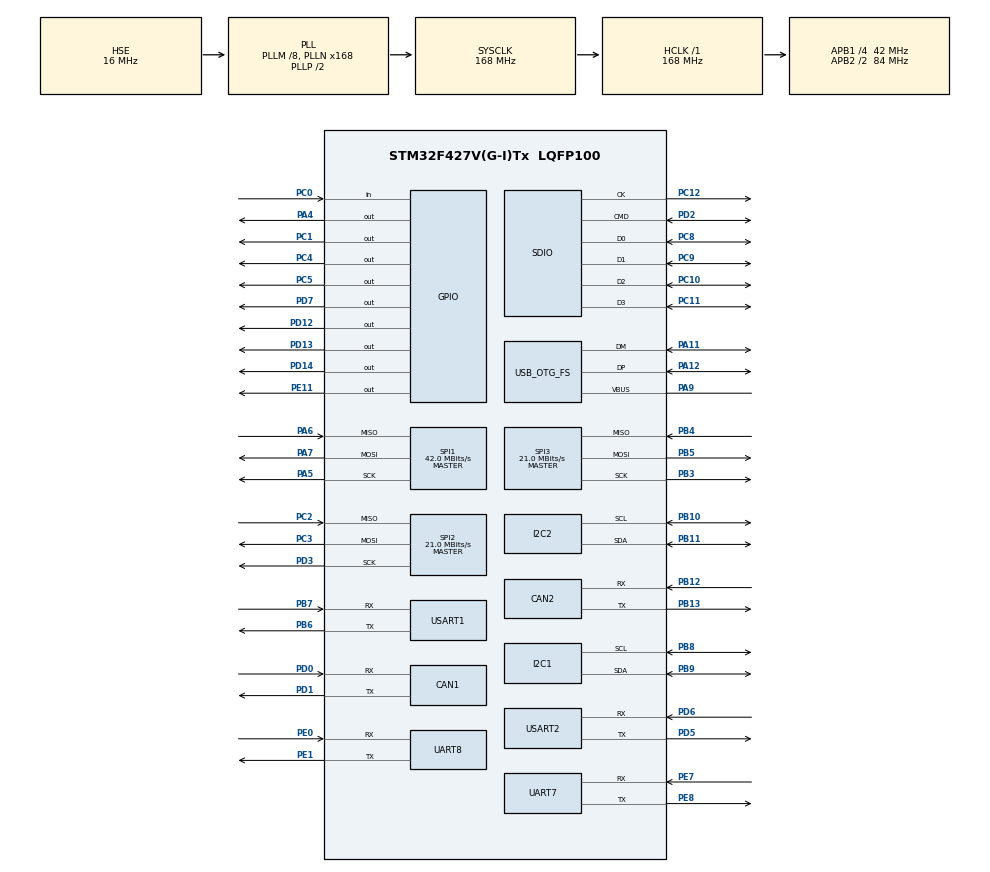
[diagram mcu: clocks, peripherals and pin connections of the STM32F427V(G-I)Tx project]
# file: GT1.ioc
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CAN1.BS1=CAN_BS1_1TQ
CAN1.BS2=CAN_BS2_1TQ
CAN1.CalculateTimeBit=1142
CAN1.CalculateTimeQuantum=380.95238095238096
CAN2.BS1=CAN_BS1_1TQ
CAN2.BS2=CAN_BS2_1TQ
CAN2.CalculateTimeBit=1142
CAN2.CalculateTimeQuantum=380.95238095238096
Mcu.Family=STM32F4
Mcu.Name=STM32F427V(G-I)Tx
Mcu.Package=LQFP100
NVIC.OTG_FS_IRQn=true\:0\:0\:false\:false\:true
NVIC.PriorityGroup=NVIC_PRIORITYGROUP_4
NVIC.TIM3_IRQn=true\:0\:0\:false\:false\:true
NVIC.TIM4_IRQn=true\:0\:0\:false\:false\:true
PA0/WKUP.Signal=UART4_TX
PA1.Signal=UART4_RX
PA11.Mode=Device_Only
PA11.Signal=USB_OTG_FS_DM
PA12.Mode=Device_Only
PA12.Signal=USB_OTG_FS_DP
PA13.Mode=Serial_Wire
PA13.Signal=SYS_JTMS-SWDIO
PA14.Mode=Serial_Wire
PA14.Signal=SYS_JTCK-SWCLK
PA4.Signal=GPIO_Output
PA5.Mode=Full_Duplex_Master
PA5.Signal=SPI1_SCK
PA6.Mode=Full_Duplex_Master
PA6.Signal=SPI1_MISO
PA7.Mode=Full_Duplex_Master
PA7.Signal=SPI1_MOSI
PA9.Mode=Activate_VBUS
PA9.Signal=USB_OTG_FS_VBUS
PB1.Signal=TIM1_CH3N
PB10.Mode=I2C
PB10.Signal=I2C2_SCL
PB11.Mode=I2C
PB11.Signal=I2C2_SDA
PB12.Mode=Slave
PB12.Signal=CAN2_RX
PB13.Mode=Slave
PB13.Signal=CAN2_TX
PB3.Mode=Full_Duplex_Master
PB3.Signal=SPI3_SCK
PB4.Mode=Full_Duplex_Master
PB4.Signal=SPI3_MISO
PB5.Mode=Full_Duplex_Master
PB5.Signal=SPI3_MOSI
PB6.Mode=Asynchronous
PB6.Signal=USART1_TX
PB7.Mode=Asynchronous
PB7.Signal=USART1_RX
PB8.Mode=I2C
PB8.Signal=I2C1_SCL
PB9.Mode=I2C
PB9.Signal=I2C1_SDA
PC0.Signal=GPIO_Input
PC1.Signal=GPIO_Output
PC10.Mode=SD_4_bits_Wide_bus
PC10.Signal=SDIO_D2
PC11.Mode=SD_4_bits_Wide_bus
PC11.Signal=SDIO_D3
PC12.Mode=SD_4_bits_Wide_bus
PC12.Signal=SDIO_CK
PC14/OSC32_IN.Mode=LSE-External-Oscillator
PC14/OSC32_IN.Signal=RCC_OSC32_IN
PC15/OSC32_OUT.Mode=LSE-External-Oscillator
PC15/OSC32_OUT.Signal=RCC_OSC32_OUT
PC2.Mode=Full_Duplex_Master
PC2.Signal=SPI2_MISO
PC3.Mode=Full_Duplex_Master
PC3.Signal=SPI2_MOSI
PC4.Signal=GPIO_Output
PC5.Signal=GPIO_Output
PC6.Signal=USART6_TX
PC7.Signal=USART6_RX
PC8.Mode=SD_4_bits_Wide_bus
PC8.Signal=SDIO_D0
PC9.Mode=SD_4_bits_Wide_bus
PC9.Signal=SDIO_D1
PD0.Mode=Master
PD0.Signal=CAN1_RX
PD1.Mode=Master
PD1.Signal=CAN1_TX
PD12.Signal=GPIO_Output
PD13.Signal=GPIO_Output
PD14.Signal=GPIO_Output
PD2.Mode=SD_4_bits_Wide_bus
PD2.Signal=SDIO_CMD
PD3.Mode=Full_Duplex_Master
PD3.Signal=SPI2_SCK
PD5.Mode=Asynchronous
PD5.Signal=USART2_TX
PD6.Mode=Asynchronous
PD6.Signal=USART2_RX
PD7.Signal=GPIO_Output
PD8.Signal=USART3_TX
PD9.Signal=USART3_RX
PE0.Mode=Asynchronous
PE0.Signal=UART8_RX
PE1.Mode=Asynchronous
PE1.Signal=UART8_TX
PE11.Signal=GPIO_Output
PE7.Mode=Asynchronous
PE7.Signal=UART7_RX
PE8.Mode=Asynchronous
PE8.Signal=UART7_TX
PH0/OSC_IN.Mode=HSE-External-Oscillator
PH0/OSC_IN.Signal=RCC_OSC_IN
PH1/OSC_OUT.Mode=HSE-External-Oscillator
PH1/OSC_OUT.Signal=RCC_OSC_OUT
ProjectManager.HeapSize=0x200
ProjectManager.StackSize=0x400
ProjectManager.TargetToolchain=MDK-ARM V5
RCC.48MHZClocksFreq_Value=48000000
RCC.AHBFreq_Value=168000000
RCC.APB1CLKDivider=RCC_HCLK_DIV4
RCC.APB1Freq_Value=42000000
RCC.APB1TimFreq_Value=84000000
RCC.APB2CLKDivider=RCC_HCLK_DIV2
RCC.APB2Freq_Value=84000000
RCC.APB2TimFreq_Value=168000000
RCC.CortexFreq_Value=168000000
RCC.HCLKFreq_Value=168000000
RCC.HSE_VALUE=16000000
RCC.HSI_VALUE=16000000
RCC.PLLM=8
RCC.PLLN=168
RCC.PLLQ=7
RCC.RCC_RTC_Clock_Source=RCC_RTCCLKSOURCE_LSI
RCC.RCC_RTC_Clock_SourceVirtual=RCC_RTCCLKSOURCE_LSE
RCC.SYSCLKFreq_VALUE=168000000
RCC.SYSCLKSource=RCC_SYSCLKSOURCE_PLLCLK
RCC.VCOOutputFreq_Value=336000000
SDIO.BusWide=SDIO_BUS_WIDE_1B
SDIO.WideMode=SDIO_BUS_WIDE_4B
SPI1.BaudRatePrescaler=SPI_BAUDRATEPRESCALER_2
SPI1.CalculateBaudRate=42.0 MBits/s
SPI1.Mode=SPI_MODE_MASTER
SPI2.BaudRatePrescaler=SPI_BAUDRATEPRESCALER_2
SPI2.CalculateBaudRate=21.0 MBits/s
SPI2.Mode=SPI_MODE_MASTER
SPI3.BaudRatePrescaler=SPI_BAUDRATEPRESCALER_2
SPI3.CalculateBaudRate=21.0 MBits/s
SPI3.Mode=SPI_MODE_MASTER
TIM3.Period=1000
TIM3.Prescaler=48000
TIM4.Period=2000
TIM4.Prescaler=42000
USB_DEVICE.CLASS_NAME-CDC_FS=CDC
USB_DEVICE.CLASS_NAME_FS=CDC
USB_DEVICE.USBD_HandleTypeDef-CDC_FS=hUsbDeviceFS
USB_DEVICE.VirtualMode-CDC_FS=Cdc
USB_DEVICE.VirtualModeFS=Cdc_FS
USB_OTG_FS.VirtualMode=Device_Only
VP_FATFS_VS_SDIO.Mode=SDIO
VP_RTC_VS_RTC_Activate.Mode=RTC_Enabled
VP_TIM3_VS_ClockSourceINT.Mode=Internal
VP_TIM4_VS_ClockSourceINT.Mode=Internal
VP_USB_DEVICE_VS_USB_DEVICE_CDC_FS.Mode=CDC_FS
board=GT1

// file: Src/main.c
/**
  ******************************************************************************
  * File Name          : main.c
  * Description        : Main program body
  ******************************************************************************
  *
  * Copyright (c) 2017 STMicroelectronics International N.V.
  * All rights reserved.
  *
  * Redistribution and use in source and binary forms, with or without
  * modification, are permitted, provided that the following conditions are met:
  *
  * 1. Redistribution of source code must retain the above copyright notice,
  *    this list of conditions and the following disclaimer.
  * 2. Redistributions in binary form must reproduce the above copyright notice,
  *    this list of conditions and the following disclaimer in the documentation
  *    and/or other materials provided with the distribution.
  * 3. Neither the name of STMicroelectronics nor the names of other
  *    contributors to this software may be used to endorse or promote products
  *    derived from this software without specific written permission.
  * 4. This software, including modifications and/or derivative works of this
  *    software, must execute solely and exclusively on microcontroller or
  *    microprocessor devices manufactured by or for STMicroelectronics.
  * 5. Redistribution and use of this software other than as permitted under
  *    this license is void and will automatically terminate your rights under
  *    this license.
  *
  * THIS SOFTWARE IS PROVIDED BY STMICROELECTRONICS AND CONTRIBUTORS "AS IS"
  * AND ANY EXPRESS, IMPLIED OR STATUTORY WARRANTIES, INCLUDING, BUT NOT
  * LIMITED TO, THE IMPLIED WARRANTIES OF MERCHANTABILITY, FITNESS FOR A
  * PARTICULAR PURPOSE AND NON-INFRINGEMENT OF THIRD PARTY INTELLECTUAL PROPERTY
  * RIGHTS ARE DISCLAIMED TO THE FULLEST EXTENT PERMITTED BY LAW. IN NO EVENT
  * SHALL STMICROELECTRONICS OR CONTRIBUTORS BE LIABLE FOR ANY DIRECT, INDIRECT,
  * INCIDENTAL, SPECIAL, EXEMPLARY, OR CONSEQUENTIAL DAMAGES (INCLUDING, BUT NOT
  * LIMITED TO, PROCUREMENT OF SUBSTITUTE GOODS OR SERVICES; LOSS OF USE, DATA,
  * OR PROFITS; OR BUSINESS INTERRUPTION) HOWEVER CAUSED AND ON ANY THEORY OF
  * LIABILITY, WHETHER IN CONTRACT, STRICT LIABILITY, OR TORT (INCLUDING
  * NEGLIGENCE OR OTHERWISE) ARISING IN ANY WAY OUT OF THE USE OF THIS SOFTWARE,
  * EVEN IF ADVISED OF THE POSSIBILITY OF SUCH DAMAGE.
  *
  ******************************************************************************
  */
#include "main.h"
#include "stm32f4xx_hal.h"
#include "fatfs.h"
#include "usb_device.h"
#include "usbd_cdc_if.h"

CAN_HandleTypeDef hcan1;
CAN_HandleTypeDef hcan2;

I2C_HandleTypeDef hi2c1;
I2C_HandleTypeDef hi2c2;

RTC_HandleTypeDef hrtc;

SD_HandleTypeDef hsd;
HAL_SD_CardInfoTypedef SDCardInfo;

SPI_HandleTypeDef hspi1;
SPI_HandleTypeDef hspi2;
SPI_HandleTypeDef hspi3;

TIM_HandleTypeDef htim3;
TIM_HandleTypeDef htim4;

UART_HandleTypeDef huart7;
UART_HandleTypeDef huart8;
UART_HandleTypeDef huart1;
UART_HandleTypeDef huart2;

int rearLight_sign = 0;
int power_sign = 0;
int paster_test_sign = 0;
/* USER CODE BEGIN PV */
/* Private variables ---------------------------------------------------------*/

/* USER CODE END PV */

void SystemClock_Config(void);
void Error_Handler(void);
static void MX_GPIO_Init(void);
static void MX_CAN1_Init(void);
static void MX_CAN2_Init(void);
static void MX_I2C1_Init(void);
static void MX_I2C2_Init(void);
static void MX_RTC_Init(void);
static void MX_SDIO_SD_Init(void);
static void MX_SPI1_Init(void);
static void MX_SPI2_Init(void);
static void MX_SPI3_Init(void);
static void MX_UART7_Init(void);
static void MX_UART8_Init(void);
static void MX_USART1_UART_Init(void);
static void MX_USART2_UART_Init(void);
static void MX_TIM4_Init(void);
static void MX_TIM3_Init(void);

/* USER CODE BEGIN PFP */
/* Private function prototypes -----------------------------------------------*/

/* USER CODE END PFP */

int main(void)
{

  /* USER CODE BEGIN 1 */
  int mdelay=0;
	int reset_num=0;
  /* USER CODE END 1 */

  /* MCU Configuration----------------------------------------------------------*/

  /* Reset of all peripherals, Initializes the Flash interface and the Systick. */
  HAL_Init();

  /* Configure the system clock */
  SystemClock_Config();

  /* Initialize all configured peripherals */
  MX_GPIO_Init();
  MX_CAN1_Init();
  MX_CAN2_Init();
  MX_I2C1_Init();
  MX_I2C2_Init();
  MX_RTC_Init();
  MX_SDIO_SD_Init();
  MX_SPI1_Init();
  MX_SPI2_Init();
  MX_SPI3_Init();
  MX_UART7_Init();
  MX_UART8_Init();
  MX_USART1_UART_Init();
  MX_USART2_UART_Init();
  MX_FATFS_Init();
  MX_TIM4_Init();
  MX_TIM3_Init();
  MX_USB_DEVICE_Init();

  /* USER CODE BEGIN 2 */
  //poweron the system
  HAL_GPIO_WritePin(GPIOE,GPIO_PIN_11,0);

  HAL_TIM_Base_Start_IT(&htim3);
	HAL_TIM_Base_Start_IT(&htim4);
  /* USER CODE END 2 */

  /* Infinite loop */
  while (1)
  {
	if(power_sign >= 3)
		HAL_GPIO_WritePin(GPIOE,GPIO_PIN_11,1);
  /* USER CODE BEGIN 3 */
	//CDC_Transmit_FS("GT1 paster test\n\r", 18);
  }
  /* USER CODE END 3 */

}

/** System Clock Configuration
*/
void SystemClock_Config(void)
{

  RCC_OscInitTypeDef RCC_OscInitStruct;
  RCC_ClkInitTypeDef RCC_ClkInitStruct;
  RCC_PeriphCLKInitTypeDef PeriphClkInitStruct;

    /**Configure the main internal regulator output voltage
    */
  __HAL_RCC_PWR_CLK_ENABLE();

  __HAL_PWR_VOLTAGESCALING_CONFIG(PWR_REGULATOR_VOLTAGE_SCALE1);

    /**Initializes the CPU, AHB and APB busses clocks
    */
  RCC_OscInitStruct.OscillatorType = RCC_OSCILLATORTYPE_LSI|RCC_OSCILLATORTYPE_HSE;
  RCC_OscInitStruct.HSEState = RCC_HSE_ON;
  RCC_OscInitStruct.LSIState = RCC_LSI_ON;
  RCC_OscInitStruct.PLL.PLLState = RCC_PLL_ON;
  RCC_OscInitStruct.PLL.PLLSource = RCC_PLLSOURCE_HSE;
  RCC_OscInitStruct.PLL.PLLM = 8;
  RCC_OscInitStruct.PLL.PLLN = 168;
  RCC_OscInitStruct.PLL.PLLP = RCC_PLLP_DIV2;
  RCC_OscInitStruct.PLL.PLLQ = 7;
  if (HAL_RCC_OscConfig(&RCC_OscInitStruct) != HAL_OK)
  {
    Error_Handler();
  }

    /**Initializes the CPU, AHB and APB busses clocks
    */
  RCC_ClkInitStruct.ClockType = RCC_CLOCKTYPE_HCLK|RCC_CLOCKTYPE_SYSCLK
                              |RCC_CLOCKTYPE_PCLK1|RCC_CLOCKTYPE_PCLK2;
  RCC_ClkInitStruct.SYSCLKSource = RCC_SYSCLKSOURCE_PLLCLK;
  RCC_ClkInitStruct.AHBCLKDivider = RCC_SYSCLK_DIV1;
  RCC_ClkInitStruct.APB1CLKDivider = RCC_HCLK_DIV4;
  RCC_ClkInitStruct.APB2CLKDivider = RCC_HCLK_DIV2;

  if (HAL_RCC_ClockConfig(&RCC_ClkInitStruct, FLASH_LATENCY_5) != HAL_OK)
  {
    Error_Handler();
  }

  PeriphClkInitStruct.PeriphClockSelection = RCC_PERIPHCLK_RTC;
  PeriphClkInitStruct.RTCClockSelection = RCC_RTCCLKSOURCE_LSI;
  if (HAL_RCCEx_PeriphCLKConfig(&PeriphClkInitStruct) != HAL_OK)
  {
    Error_Handler();
  }

    /**Configure the Systick interrupt time
    */
  HAL_SYSTICK_Config(HAL_RCC_GetHCLKFreq()/1000);

    /**Configure the Systick
    */
  HAL_SYSTICK_CLKSourceConfig(SYSTICK_CLKSOURCE_HCLK);

  /* SysTick_IRQn interrupt configuration */
  HAL_NVIC_SetPriority(SysTick_IRQn, 0, 0);
}

/* CAN1 init function */
static void MX_CAN1_Init(void)
{

  hcan1.Instance = CAN1;
  hcan1.Init.Prescaler = 16;
  hcan1.Init.Mode = CAN_MODE_NORMAL;
  hcan1.Init.SJW = CAN_SJW_1TQ;
  hcan1.Init.BS1 = CAN_BS1_1TQ;
  hcan1.Init.BS2 = CAN_BS2_1TQ;
  hcan1.Init.TTCM = DISABLE;
  hcan1.Init.ABOM = DISABLE;
  hcan1.Init.AWUM = DISABLE;
  hcan1.Init.NART = DISABLE;
  hcan1.Init.RFLM = DISABLE;
  hcan1.Init.TXFP = DISABLE;
  if (HAL_CAN_Init(&hcan1) != HAL_OK)
  {
    Error_Handler();
  }

}

/* CAN2 init function */
static void MX_CAN2_Init(void)
{

  hcan2.Instance = CAN2;
  hcan2.Init.Prescaler = 16;
  hcan2.Init.Mode = CAN_MODE_NORMAL;
  hcan2.Init.SJW = CAN_SJW_1TQ;
  hcan2.Init.BS1 = CAN_BS1_1TQ;
  hcan2.Init.BS2 = CAN_BS2_1TQ;
  hcan2.Init.TTCM = DISABLE;
  hcan2.Init.ABOM = DISABLE;
  hcan2.Init.AWUM = DISABLE;
  hcan2.Init.NART = DISABLE;
  hcan2.Init.RFLM = DISABLE;
  hcan2.Init.TXFP = DISABLE;
  if (HAL_CAN_Init(&hcan2) != HAL_OK)
  {
    Error_Handler();
  }

}

/* I2C1 init function */
static void MX_I2C1_Init(void)
{

  hi2c1.Instance = I2C1;
  hi2c1.Init.ClockSpeed = 100000;
  hi2c1.Init.DutyCycle = I2C_DUTYCYCLE_2;
  hi2c1.Init.OwnAddress1 = 0;
  hi2c1.Init.AddressingMode = I2C_ADDRESSINGMODE_7BIT;
  hi2c1.Init.DualAddressMode = I2C_DUALADDRESS_DISABLE;
  hi2c1.Init.OwnAddress2 = 0;
  hi2c1.Init.GeneralCallMode = I2C_GENERALCALL_DISABLE;
  hi2c1.Init.NoStretchMode = I2C_NOSTRETCH_DISABLE;
  if (HAL_I2C_Init(&hi2c1) != HAL_OK)
  {
    Error_Handler();
  }

}

/* I2C2 init function */
static void MX_I2C2_Init(void)
{

  hi2c2.Instance = I2C2;
  hi2c2.Init.ClockSpeed = 100000;
  hi2c2.Init.DutyCycle = I2C_DUTYCYCLE_2;
  hi2c2.Init.OwnAddress1 = 0;
  hi2c2.Init.AddressingMode = I2C_ADDRESSINGMODE_7BIT;
  hi2c2.Init.DualAddressMode = I2C_DUALADDRESS_DISABLE;
  hi2c2.Init.OwnAddress2 = 0;
  hi2c2.Init.GeneralCallMode = I2C_GENERALCALL_DISABLE;
  hi2c2.Init.NoStretchMode = I2C_NOSTRETCH_DISABLE;
  if (HAL_I2C_Init(&hi2c2) != HAL_OK)
  {
    Error_Handler();
  }

}

/* RTC init function */
static void MX_RTC_Init(void)
{

    /**Initialize RTC Only
    */
  hrtc.Instance = RTC;
  hrtc.Init.HourFormat = RTC_HOURFORMAT_24;
  hrtc.Init.AsynchPrediv = 127;
  hrtc.Init.SynchPrediv = 255;
  hrtc.Init.OutPut = RTC_OUTPUT_DISABLE;
  hrtc.Init.OutPutPolarity = RTC_OUTPUT_POLARITY_HIGH;
  hrtc.Init.OutPutType = RTC_OUTPUT_TYPE_OPENDRAIN;
  if (HAL_RTC_Init(&hrtc) != HAL_OK)
  {
    Error_Handler();
  }

}

/* SDIO init function */
static void MX_SDIO_SD_Init(void)
{

  hsd.Instance = SDIO;
  hsd.Init.ClockEdge = SDIO_CLOCK_EDGE_RISING;
  hsd.Init.ClockBypass = SDIO_CLOCK_BYPASS_DISABLE;
  hsd.Init.ClockPowerSave = SDIO_CLOCK_POWER_SAVE_DISABLE;
  hsd.Init.BusWide = SDIO_BUS_WIDE_1B;
  hsd.Init.HardwareFlowControl = SDIO_HARDWARE_FLOW_CONTROL_DISABLE;
  hsd.Init.ClockDiv = 0;

}

/* SPI1 init function */
static void MX_SPI1_Init(void)
{

  hspi1.Instance = SPI1;
  hspi1.Init.Mode = SPI_MODE_MASTER;
  hspi1.Init.Direction = SPI_DIRECTION_2LINES;
  hspi1.Init.DataSize = SPI_DATASIZE_8BIT;
  hspi1.Init.CLKPolarity = SPI_POLARITY_LOW;
  hspi1.Init.CLKPhase = SPI_PHASE_1EDGE;
  hspi1.Init.NSS = SPI_NSS_SOFT;
  hspi1.Init.BaudRatePrescaler = SPI_BAUDRATEPRESCALER_2;
  hspi1.Init.FirstBit = SPI_FIRSTBIT_MSB;
  hspi1.Init.TIMode = SPI_TIMODE_DISABLE;
  hspi1.Init.CRCCalculation = SPI_CRCCALCULATION_DISABLE;
  hspi1.Init.CRCPolynomial = 10;
  if (HAL_SPI_Init(&hspi1) != HAL_OK)
  {
    Error_Handler();
  }

}

/* SPI2 init function */
static void MX_SPI2_Init(void)
{

  hspi2.Instance = SPI2;
  hspi2.Init.Mode = SPI_MODE_MASTER;
  hspi2.Init.Direction = SPI_DIRECTION_2LINES;
  hspi2.Init.DataSize = SPI_DATASIZE_8BIT;
  hspi2.Init.CLKPolarity = SPI_POLARITY_LOW;
  hspi2.Init.CLKPhase = SPI_PHASE_1EDGE;
  hspi2.Init.NSS = SPI_NSS_SOFT;
  hspi2.Init.BaudRatePrescaler = SPI_BAUDRATEPRESCALER_2;
  hspi2.Init.FirstBit = SPI_FIRSTBIT_MSB;
  hspi2.Init.TIMode = SPI_TIMODE_DISABLE;
  hspi2.Init.CRCCalculation = SPI_CRCCALCULATION_DISABLE;
  hspi2.Init.CRCPolynomial = 10;
  if (HAL_SPI_Init(&hspi2) != HAL_OK)
  {
    Error_Handler();
  }

}

/* SPI3 init function */
static void MX_SPI3_Init(void)
{

  hspi3.Instance = SPI3;
  hspi3.Init.Mode = SPI_MODE_MASTER;
  hspi3.Init.Direction = SPI_DIRECTION_2LINES;
  hspi3.Init.DataSize = SPI_DATASIZE_8BIT;
  hspi3.Init.CLKPolarity = SPI_POLARITY_LOW;
  hspi3.Init.CLKPhase = SPI_PHASE_1EDGE;
  hspi3.Init.NSS = SPI_NSS_SOFT;
  hspi3.Init.BaudRatePrescaler = SPI_BAUDRATEPRESCALER_2;
  hspi3.Init.FirstBit = SPI_FIRSTBIT_MSB;
  hspi3.Init.TIMode = SPI_TIMODE_DISABLE;
  hspi3.Init.CRCCalculation = SPI_CRCCALCULATION_DISABLE;
  hspi3.Init.CRCPolynomial = 10;
  if (HAL_SPI_Init(&hspi3) != HAL_OK)
  {
    Error_Handler();
  }

}

/* TIM3 init function */
static void MX_TIM3_Init(void)
{

  TIM_ClockConfigTypeDef sClockSourceConfig;
  TIM_MasterConfigTypeDef sMasterConfig;

  htim3.Instance = TIM3;
  htim3.Init.Prescaler = 48000;
  htim3.Init.CounterMode = TIM_COUNTERMODE_UP;
  htim3.Init.Period = 1000;
  htim3.Init.ClockDivision = TIM_CLOCKDIVISION_DIV1;
  if (HAL_TIM_Base_Init(&htim3) != HAL_OK)
  {
    Error_Handler();
  }

  sClockSourceConfig.ClockSource = TIM_CLOCKSOURCE_INTERNAL;
  if (HAL_TIM_ConfigClockSource(&htim3, &sClockSourceConfig) != HAL_OK)
  {
    Error_Handler();
  }

  sMasterConfig.MasterOutputTrigger = TIM_TRGO_RESET;
  sMasterConfig.MasterSlaveMode = TIM_MASTERSLAVEMODE_DISABLE;
  if (HAL_TIMEx_MasterConfigSynchronization(&htim3, &sMasterConfig) != HAL_OK)
  {
    Error_Handler();
  }

}

/* TIM4 init function */
static void MX_TIM4_Init(void)
{

  TIM_ClockConfigTypeDef sClockSourceConfig;
  TIM_MasterConfigTypeDef sMasterConfig;

  htim4.Instance = TIM4;
  htim4.Init.Prescaler = 42000;
  htim4.Init.CounterMode = TIM_COUNTERMODE_UP;
  htim4.Init.Period = 2000;
  htim4.Init.ClockDivision = TIM_CLOCKDIVISION_DIV1;
  if (HAL_TIM_Base_Init(&htim4) != HAL_OK)
  {
    Error_Handler();
  }

  sClockSourceConfig.ClockSource = TIM_CLOCKSOURCE_INTERNAL;
  if (HAL_TIM_ConfigClockSource(&htim4, &sClockSourceConfig) != HAL_OK)
  {
    Error_Handler();
  }

  sMasterConfig.MasterOutputTrigger = TIM_TRGO_RESET;
  sMasterConfig.MasterSlaveMode = TIM_MASTERSLAVEMODE_DISABLE;
  if (HAL_TIMEx_MasterConfigSynchronization(&htim4, &sMasterConfig) != HAL_OK)
  {
    Error_Handler();
  }

}

/* UART7 init function */
static void MX_UART7_Init(void)
{

  huart7.Instance = UART7;
  huart7.Init.BaudRate = 115200;
  huart7.Init.WordLength = UART_WORDLENGTH_8B;
  huart7.Init.StopBits = UART_STOPBITS_1;
  huart7.Init.Parity = UART_PARITY_NONE;
  huart7.Init.Mode = UART_MODE_TX_RX;
  huart7.Init.HwFlowCtl = UART_HWCONTROL_NONE;
  huart7.Init.OverSampling = UART_OVERSAMPLING_16;
  if (HAL_UART_Init(&huart7) != HAL_OK)
  {
    Error_Handler();
  }

}

/* UART8 init function */
static void MX_UART8_Init(void)
{

  huart8.Instance = UART8;
  huart8.Init.BaudRate = 115200;
  huart8.Init.WordLength = UART_WORDLENGTH_8B;
  huart8.Init.StopBits = UART_STOPBITS_1;
  huart8.Init.Parity = UART_PARITY_NONE;
  huart8.Init.Mode = UART_MODE_TX_RX;
  huart8.Init.HwFlowCtl = UART_HWCONTROL_NONE;
  huart8.Init.OverSampling = UART_OVERSAMPLING_16;
  if (HAL_UART_Init(&huart8) != HAL_OK)
  {
    Error_Handler();
  }

}

/* USART1 init function */
static void MX_USART1_UART_Init(void)
{

  huart1.Instance = USART1;
  huart1.Init.BaudRate = 115200;
  huart1.Init.WordLength = UART_WORDLENGTH_8B;
  huart1.Init.StopBits = UART_STOPBITS_1;
  huart1.Init.Parity = UART_PARITY_NONE;
  huart1.Init.Mode = UART_MODE_TX_RX;
  huart1.Init.HwFlowCtl = UART_HWCONTROL_NONE;
  huart1.Init.OverSampling = UART_OVERSAMPLING_16;
  if (HAL_UART_Init(&huart1) != HAL_OK)
  {
    Error_Handler();
  }

}

/* USART2 init function */
static void MX_USART2_UART_Init(void)
{

  huart2.Instance = USART2;
  huart2.Init.BaudRate = 115200;
  huart2.Init.WordLength = UART_WORDLENGTH_8B;
  huart2.Init.StopBits = UART_STOPBITS_1;
  huart2.Init.Parity = UART_PARITY_NONE;
  huart2.Init.Mode = UART_MODE_TX_RX;
  huart2.Init.HwFlowCtl = UART_HWCONTROL_NONE;
  huart2.Init.OverSampling = UART_OVERSAMPLING_16;
  if (HAL_UART_Init(&huart2) != HAL_OK)
  {
    Error_Handler();
  }

}

/** Configure pins as
        * Analog
        * Input
        * Output
        * EVENT_OUT
        * EXTI
     PA0/WKUP   ------> UART4_TX
     PA1   ------> UART4_RX
     PB1   ------> TIM1_CH3N
     PD8   ------> USART3_TX
     PD9   ------> USART3_RX
     PC6   ------> USART6_TX
     PC7   ------> USART6_RX
*/
static void MX_GPIO_Init(void)
{

  GPIO_InitTypeDef GPIO_InitStruct;

  /* GPIO Ports Clock Enable */
  __HAL_RCC_GPIOC_CLK_ENABLE();
  __HAL_RCC_GPIOH_CLK_ENABLE();
  __HAL_RCC_GPIOA_CLK_ENABLE();
  __HAL_RCC_GPIOB_CLK_ENABLE();
  __HAL_RCC_GPIOE_CLK_ENABLE();
  __HAL_RCC_GPIOD_CLK_ENABLE();

  /*Configure GPIO pin : PC0 */
  GPIO_InitStruct.Pin = GPIO_PIN_0;
  GPIO_InitStruct.Mode = GPIO_MODE_INPUT;
  GPIO_InitStruct.Pull = GPIO_NOPULL;
  HAL_GPIO_Init(GPIOC, &GPIO_InitStruct);

  /*Configure GPIO pins : PC1 PC4 PC5 */
  GPIO_InitStruct.Pin = GPIO_PIN_1|GPIO_PIN_4|GPIO_PIN_5;
  GPIO_InitStruct.Mode = GPIO_MODE_OUTPUT_PP;
  GPIO_InitStruct.Pull = GPIO_NOPULL;
  GPIO_InitStruct.Speed = GPIO_SPEED_FREQ_LOW;
  HAL_GPIO_Init(GPIOC, &GPIO_InitStruct);

  /*Configure GPIO pins : PA0 PA1 */
  GPIO_InitStruct.Pin = GPIO_PIN_0|GPIO_PIN_1;
  GPIO_InitStruct.Mode = GPIO_MODE_AF_PP;
  GPIO_InitStruct.Pull = GPIO_NOPULL;
  GPIO_InitStruct.Speed = GPIO_SPEED_FREQ_VERY_HIGH;
  GPIO_InitStruct.Alternate = GPIO_AF8_UART4;
  HAL_GPIO_Init(GPIOA, &GPIO_InitStruct);

  /*Configure GPIO pin : PA4 */
  GPIO_InitStruct.Pin = GPIO_PIN_4;
  GPIO_InitStruct.Mode = GPIO_MODE_OUTPUT_PP;
  GPIO_InitStruct.Pull = GPIO_NOPULL;
  GPIO_InitStruct.Speed = GPIO_SPEED_FREQ_LOW;
  HAL_GPIO_Init(GPIOA, &GPIO_InitStruct);

  /*Configure GPIO pin : PB1 */
  GPIO_InitStruct.Pin = GPIO_PIN_1;
  GPIO_InitStruct.Mode = GPIO_MODE_AF_PP;
  GPIO_InitStruct.Pull = GPIO_NOPULL;
  GPIO_InitStruct.Speed = GPIO_SPEED_FREQ_LOW;
  GPIO_InitStruct.Alternate = GPIO_AF1_TIM1;
  HAL_GPIO_Init(GPIOB, &GPIO_InitStruct);

  /*Configure GPIO pin : PE11 */
  GPIO_InitStruct.Pin = GPIO_PIN_11|GPIO_PIN_9;
  GPIO_InitStruct.Mode = GPIO_MODE_OUTPUT_PP;
  GPIO_InitStruct.Pull = GPIO_NOPULL;
  GPIO_InitStruct.Speed = GPIO_SPEED_FREQ_LOW;
  HAL_GPIO_Init(GPIOE, &GPIO_InitStruct);

  /*Configure GPIO pins : PD8 PD9 */
  GPIO_InitStruct.Pin = GPIO_PIN_8|GPIO_PIN_9;
  GPIO_InitStruct.Mode = GPIO_MODE_AF_PP;
  GPIO_InitStruct.Pull = GPIO_NOPULL;
  GPIO_InitStruct.Speed = GPIO_SPEED_FREQ_VERY_HIGH;
  GPIO_InitStruct.Alternate = GPIO_AF7_USART3;
  HAL_GPIO_Init(GPIOD, &GPIO_InitStruct);

  /*Configure GPIO pins : PD12 PD13 PD14 PD7 */
  GPIO_InitStruct.Pin = GPIO_PIN_12|GPIO_PIN_13|GPIO_PIN_14|GPIO_PIN_7;
  GPIO_InitStruct.Mode = GPIO_MODE_OUTPUT_PP;
  GPIO_InitStruct.Pull = GPIO_NOPULL;
  GPIO_InitStruct.Speed = GPIO_SPEED_FREQ_LOW;
  HAL_GPIO_Init(GPIOD, &GPIO_InitStruct);

  /*Configure GPIO pins : PC6 PC7 */
  GPIO_InitStruct.Pin = GPIO_PIN_6|GPIO_PIN_7;
  GPIO_InitStruct.Mode = GPIO_MODE_AF_PP;
  GPIO_InitStruct.Pull = GPIO_NOPULL;
  GPIO_InitStruct.Speed = GPIO_SPEED_FREQ_VERY_HIGH;
  GPIO_InitStruct.Alternate = GPIO_AF8_USART6;
  HAL_GPIO_Init(GPIOC, &GPIO_InitStruct);

  /*Configure GPIO pin Output Level */
  HAL_GPIO_WritePin(GPIOC, GPIO_PIN_1|GPIO_PIN_4|GPIO_PIN_5, GPIO_PIN_RESET);

  /*Configure GPIO pin Output Level */
  HAL_GPIO_WritePin(GPIOA, GPIO_PIN_4, GPIO_PIN_RESET);

  /*Configure GPIO pin Output Level */
  HAL_GPIO_WritePin(GPIOE, GPIO_PIN_11, GPIO_PIN_RESET);

  /*Configure GPIO pin Output Level */
  HAL_GPIO_WritePin(GPIOD, GPIO_PIN_12|GPIO_PIN_13|GPIO_PIN_14|GPIO_PIN_7, GPIO_PIN_RESET);

}

void Error_Handler(void)
{
  while(1)
  {
  }
}

/************************ (C) COPYRIGHT STMicroelectronics *****END OF FILE****/
